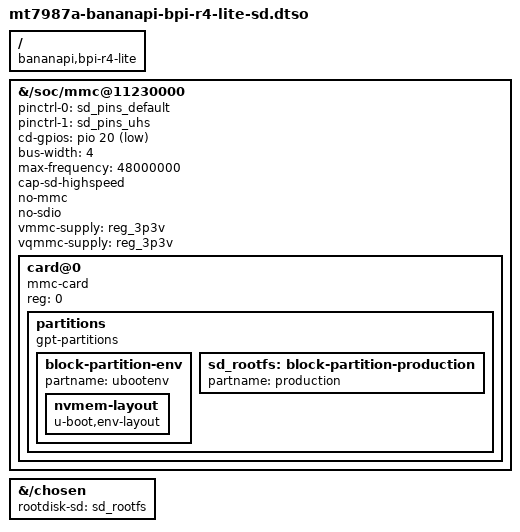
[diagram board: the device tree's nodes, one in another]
/dts-v1/;
/plugin/;

#include <dt-bindings/gpio/gpio.h>

/ {
	compatible = "bananapi,bpi-r4-lite",
		     "mediatek,mt7987a", "mediatek,mt7987";
};

&{/soc/mmc@11230000} {
	pinctrl-names = "default", "state_uhs";
	pinctrl-0 = <&sd_pins_default>;
	pinctrl-1 = <&sd_pins_uhs>;
	cd-gpios = <&pio 20 GPIO_ACTIVE_LOW>;

	bus-width = <4>;
	max-frequency = <48000000>;
	cap-sd-highspeed;
	no-mmc;
	no-sdio;
	vmmc-supply = <&reg_3p3v>;
	vqmmc-supply = <&reg_3p3v>;

	#address-cells = <1>;
	#size-cells = <0>;

	status = "okay";

	card@0 {
		compatible = "mmc-card";
		reg = <0>;

		partitions {
			compatible = "gpt-partitions";

			block-partition-env {
				partname = "ubootenv";
				nvmem-layout {
					compatible = "u-boot,env-layout";
				};
			};

			sd_rootfs: block-partition-production {
				partname = "production";
			};
		};
	};
};

&{/chosen} {
	rootdisk-sd = <&sd_rootfs>;
};
